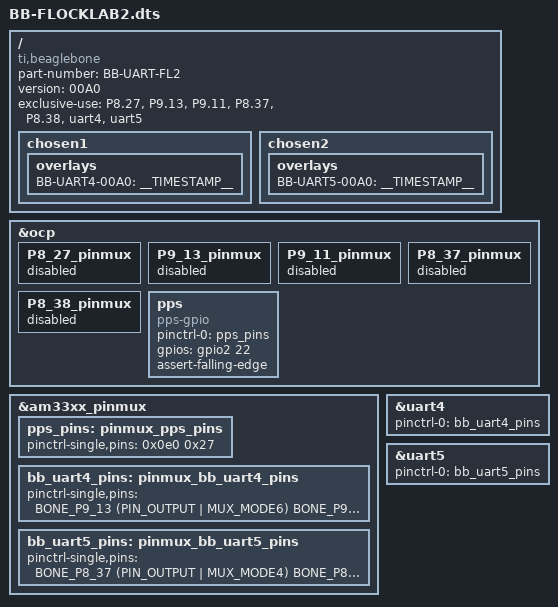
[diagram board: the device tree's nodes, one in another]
/*
 * Copyright (C) 2013 CircuitCo
 *
 * Virtual cape for UART5 on connector pins P9.37 P8.38
 *
 * This program is free software; you can redistribute it and/or modify
 * it under the terms of the GNU General Public License version 2 as
 * published by the Free Software Foundation.
 */

/dts-v1/;
/plugin/;

#include <dt-bindings/board/am335x-bbw-bbb-base.h>
#include <dt-bindings/pinctrl/am33xx.h>

/ {
	compatible = "ti,beaglebone", "ti,beaglebone-black", "ti,beaglebone-green";

	// identification
	part-number = "BB-UART-FL2";
	version = "00A0";

	// resources this cape uses
	exclusive-use =
		"P8.27",		// pps gpio
		"P9.13",		// uart4_txd
		"P9.11",		// uart4_rxd
		"P8.37",		// uart5_txd
		"P8.38",		// uart5_rxd

		"uart4",		// hardware ip used
		"uart5";		// hardware ip used

	/*
	 * Helper to show loaded overlays under: /proc/device-tree/chosen/overlays/
	 */
	fragment@0 {
		target-path="/";
		__overlay__ {
			chosen1 {
				overlays {
					BB-UART4-00A0 = __TIMESTAMP__;
				};
			};
			chosen2 {
				overlays {
					BB-UART5-00A0 = __TIMESTAMP__;
				};
			};
		};
	};



	/*
	 * Free up the pins used by the cape from the pinmux helpers.
	 */
	fragment@1 {
		target = <&ocp>;
		__overlay__ {
			P8_27_pinmux { status = "disabled"; };	/* pps */
			P9_13_pinmux { status = "disabled"; };	/* uart4_txd */
			P9_11_pinmux { status = "disabled"; };	/* uart4_rxd */
			P8_37_pinmux { status = "disabled"; };	/* uart5_txd */
			P8_38_pinmux { status = "disabled"; };	/* uart5_rxd */
		};
	};

	fragment@2 {
		target = <&am33xx_pinmux>;
		__overlay__ {
			pps_pins: pinmux_pps_pins {
				pinctrl-single,pins = <
					0x0e0	0x27	/* gpmc_a0.gpio2_23, INPUT | PULLDIS | MODE7 */
				>;
			};
			bb_uart4_pins: pinmux_bb_uart4_pins {
				pinctrl-single,pins = <
					BONE_P9_13 (PIN_OUTPUT | MUX_MODE6)	// gpmc_wpn.uart4_txd_mux2
					BONE_P9_11 (PIN_INPUT  | MUX_MODE6)	// gpmc_wait0.uart4_rxd_mux2
				>;
			};
			bb_uart5_pins: pinmux_bb_uart5_pins {
				pinctrl-single,pins = <
					BONE_P8_37 (PIN_OUTPUT | MUX_MODE4)	// lcd_data8.uart5_txd
					BONE_P8_38 (PIN_INPUT  | MUX_MODE4)	// lcd_data9.uart5_rxd
				>;
			};
		};
	};

	fragment@3 {
		target = <&ocp>;
		__overlay__ {
			pps {
				compatible = "pps-gpio";
				status = "okay";
				pinctrl-names = "default";
				pinctrl-0 = <&pps_pins>;

				gpios = <&gpio2 22 0>;
				assert-falling-edge;
			};
		};
	};

	fragment@4 {
		target = <&uart4>;
		__overlay__ {
			status = "okay";
			pinctrl-names = "default";
			pinctrl-0 = <&bb_uart4_pins>;
		};
	};

	fragment@5 {
		target = <&uart5>;
		__overlay__ {
			status = "okay";
			pinctrl-names = "default";
			pinctrl-0 = <&bb_uart5_pins>;
		};
	};
};
